# ADuCM355 register map
Vendor: Analog Devices; Series: ADuCM355; File version: 1p0
CPU: CM3 r0p1, little endian, no MPU, no FPU, 3 interrupt priority bits
Registers are 32-bit, read-write, reset 0x0 unless marked. A register's access mark holds for its fields unless they carry their own. Offsets are from the block's base; [hi:lo] are bit positions.

## TMR0 — General Purpose Timer
Base 0x40000000
Same registers: TMR1 0x40000400, TMR2 0x40000800
0x00 LOAD 16-bit — 16-bit load value
  [15:0] VALUE range 0x00000000..0x0000FFFF — Load value
0x04 CURCNT 16-bit — 16-bit timer value
  [15:0] VALUE ro — Current count
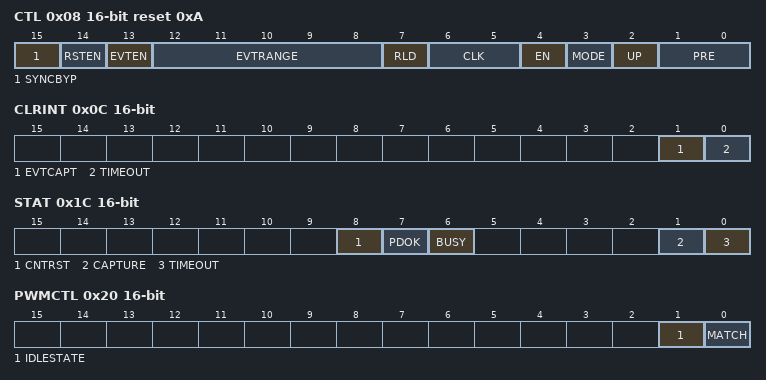
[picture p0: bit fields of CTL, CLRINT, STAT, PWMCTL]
0x08 CTL 16-bit reset 0xA — Control
  [15] SYNCBYP range 0x00000000..0x00000001 — Synchronization bypass
  [14] RSTEN range 0x00000000..0x00000001 — Counter and prescale reset enable
  [13] EVTEN — Event select
  [12:8] EVTRANGE range 0x00000000..0x0000001F — Event select range
  [7] RLD — Reload control
  [6:5] CLK — Clock select
  [4] EN — Timer enable
  [3] MODE — Timer mode
  [2] UP — Count up
  [1:0] PRE — Prescaler
0x0C CLRINT 16-bit — Clear Interrupt
  [1] EVTCAPT wo — Clear captured event interrupt
  [0] TIMEOUT wo — Clear timeout interrupt
0x10 CAPTURE 16-bit
  [15:0] VALUE ro — 16-bit captured value
0x14 ALOAD 16-bit — 16-bit load value, asynchronous
  [15:0] VALUE range 0x00000000..0x0000FFFF — Load value, asynchronous
0x18 ACURCNT 16-bit — 16-bit timer value, asynchronous
  [15:0] VALUE ro — Counter value
0x1C STAT 16-bit — Status
  [8] CNTRST ro — Counter reset occurring
  [7] PDOK ro — Clear Interrupt Register synchronization
  [6] BUSY ro — Timer Busy
  [1] CAPTURE ro — Capture event pending
  [0] TIMEOUT ro — Timeout event occurred
0x20 PWMCTL 16-bit — PWM Control Register
  [1] IDLESTATE range 0x00000000..0x00000001 — PWM Idle State
  [0] MATCH range 0x00000000..0x00000001 — PWM Match enabled
0x24 PWMMATCH 16-bit — PWM Match Value
  [15:0] VALUE range 0x00000000..0x0000FFFF

## SYS — System Identification and Debug Enable
Base 0x40002000
0x20 ADIID 16-bit reset 0x4144 — ADI Identification
  [15:0] VALUE ro — Reads a fixed value of 0x4144 to indicate to debuggers that they are connected to an Analog Devices implemented Cortex based part
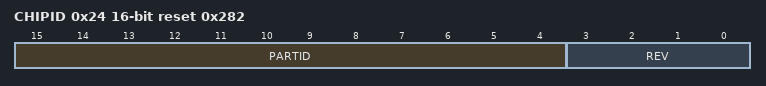
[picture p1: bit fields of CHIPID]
0x24 CHIPID 16-bit reset 0x282 — Chip Identifier
  [15:4] PARTID ro — Part identifier
  [3:0] REV ro — Silicon revision
0x40 SWDEN 16-bit reset 0x7072 — Serial Wire Debug Enable
  [15:0] VALUE wo range 0x00000000..0x0000FFFF — To enable SWD interface

## WDT0 — Watchdog Timer
Base 0x40002C00
0x00 LOAD 16-bit reset 0x1000 — Load value
  [15:0] VALUE range 0x00000000..0x0000FFFF
0x04 CCNT 16-bit reset 0x1000 — Current count value
  [15:0] VALUE ro
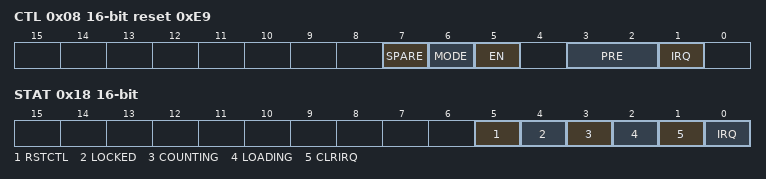
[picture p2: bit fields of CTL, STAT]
0x08 CTL 16-bit reset 0xE9 — Control
  [7] SPARE range 0x00000000..0x00000001 — Unused spare bit
  [6] MODE range 0x00000000..0x00000001 — Timer mode
  [5] EN range 0x00000000..0x00000001 — Timer enable
  [3:2] PRE — Prescaler
    0=div1 (source clock/1.); 1=div16 (source clock/16.); 2=div256 (source clock/256 (default).)
  [1] IRQ range 0x00000000..0x00000001 — Timer interrupt
0x0C RESTART 16-bit — Clear interrupt
  [15:0] CLRWORD wo range 0x00000000..0x0000FFFF — Clear watchdog
0x18 STAT 16-bit — Status
  [5] RSTCTL ro — Reset Control Register written and locked
  [4] LOCKED ro — Lock status bit
  [3] COUNTING ro — Control Register write sync in progress
  [2] LOADING ro — Load Register write sync in progress
  [1] CLRIRQ ro — Clear Interrupt Register write sync in progress
  [0] IRQ ro — WDT Interrupt

## DMA0 — DMA
Base 0x40010000
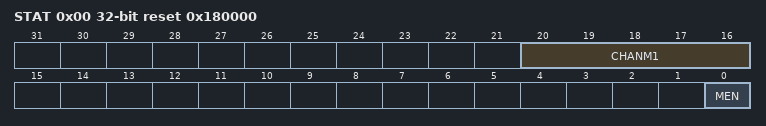
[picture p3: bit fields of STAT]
0x00 STAT reset 0x180000 — DMA Status
  [20:16] CHANM1 ro — Number of available DMA channels minus 1
  [0] MEN ro — Enable status of the controller
0x04 CFG — DMA Configuration
  [0] MEN wo — Controller enable
0x08 PDBPTR — DMA channel primary control data base pointer
  [31:0] ADDR range 0x00000000..0xFFFFFFFF — Pointer to the base address of the primary data structure
0x0C ADBPTR reset 0x200 — DMA channel alternate control data base pointer
  [31:0] ADDR ro — Base address of the alternate data structure
0x14 SWREQ — DMA channel software request
  [23:0] CHAN wo range 0x00000000..0x00FFFFFF — Generate software request
0x20 RMSK_SET — DMA channel request mask set
  [23:0] CHAN range 0x00000000..0x00FFFFFF — Mask requests from DMA channels
0x24 RMSK_CLR — DMA channel request mask clear
  [23:0] CHAN wo range 0x00000000..0x00FFFFFF — Clear Request Mask Set bits
0x28 EN_SET — DMA channel enable set
  [23:0] CHAN range 0x00000000..0x00FFFFFF — Enable DMA channels
0x2C EN_CLR — DMA channel enable clear
  [23:0] CHAN wo range 0x00000000..0x00FFFFFF — Disable DMA channels
0x30 ALT_SET — DMA channel primary-alternate set
  [23:0] CHAN range 0x00000000..0x00FFFFFF — Control struct status / select alt struct
0x34 ALT_CLR — DMA channel primary-alternate clear
  [23:0] CHAN wo range 0x00000000..0x00FFFFFF — Select primary data struct
0x38 PRI_SET — DMA channel priority set
  [23:0] CHAN wo range 0x00000000..0x00FFFFFF — Configure channel for high priority
0x3C PRI_CLR — DMA channel priority clear
  [23:0] CHPRICLR wo range 0x00000000..0x00FFFFFF — Configure channel for default priority level
0x48 ERRCHNL_CLR — DMA Per Channel Error Clear
  [23:0] CHAN range 0x00000000..0x00FFFFFF — Per channel Bus error status/ Per channel bus error clear
0x4C ERR_CLR — DMA bus error clear
  [23:0] CHAN range 0x00000000..0x00FFFFFF — Bus error status
0x50 INVALIDDESC_CLR — DMA Per Channel Invalid Descriptor Clear
  [23:0] CHAN range 0x00000000..0x00FFFFFF — Per channel Invalid Descriptor status/ Per channel Invalid descriptor status clear
0x800 BS_SET — DMA channel bytes swap enable set
  [23:0] CHAN range 0x00000000..0x00FFFFFF — Byte swap status
0x804 BS_CLR — DMA channel bytes swap enable clear
  [23:0] CHAN wo range 0x00000000..0x00FFFFFF — Disable byte swap
0x810 SRCADDR_SET — DMA channel source address decrement enable set
  [23:0] CHAN range 0x00000000..0x00FFFFFF — Source Address decrement status / configure Source address decrement
0x814 SRCADDR_CLR — DMA channel source address decrement enable clear
  [23:0] CHAN wo range 0x00000000..0x00FFFFFF — Disable source address decrement
0x818 DSTADDR_SET — DMA channel destination address decrement enable set
  [23:0] CHAN range 0x00000000..0x00FFFFFF — Destination Address decrement status / configure destination address decrement
0x81C DSTADDR_CLR — DMA channel destination address decrement enable clear
  [23:0] CHAN wo range 0x00000000..0x00FFFFFF — Disable destination address decrement
0xFE0 REVID reset 0x2 — DMA Controller Revision ID
  [7:0] VALUE ro — DMA Controller revision ID
